# RSL15 register map
Vendor: ONSemiconductor; Series: RSL15 Series; File version: 1.0
CPU: CM33 r0p4, little endian, MPU, FPU, 3 interrupt priority bits
Registers are 32-bit, read-write, reset 0x0 unless marked. A register's access mark holds for its fields unless they carry their own. Offsets are from the block's base; [hi:lo] are bit positions.

## SPI0 — SPI Interface
Base 0x40000B00
Same registers: SPI1 0x40000C00
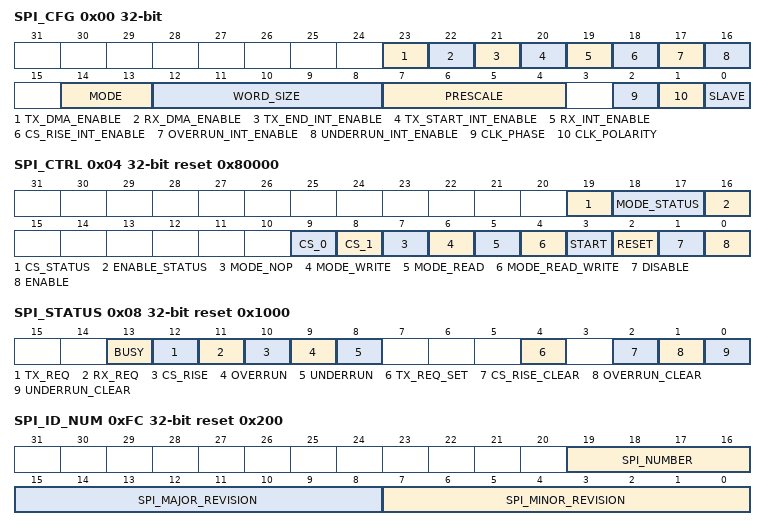
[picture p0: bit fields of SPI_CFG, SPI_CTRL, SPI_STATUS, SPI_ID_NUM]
0x00 SPI_CFG — SPI Configuration Register
  [23] TX_DMA_ENABLE — Enable/disable the TX DMA request
    0=SPI_TX_DMA_DISABLE (No TX DMA request is generated); 1=SPI_TX_DMA_ENABLE (A TX DMA request is generated when TX buffer is empty)
  [22] RX_DMA_ENABLE — Enable/disable the RX DMA request
    0=SPI_RX_DMA_DISABLE (No RX DMA request is generated); 1=SPI_RX_DMA_ENABLE (An RX DMA request is generated when RX buffer is full)
  [21] TX_END_INT_ENABLE — Enable/disable the TX interrupt
    0=SPI_TX_END_INT_DISABLE (No TX interrupt is raised); 1=SPI_TX_END_INT_ENABLE (A TX interrupt is raised when a TX data transmission is finished)
  [20] TX_START_INT_ENABLE — Enable/disable the TX interrupt
    0=SPI_TX_START_INT_DISABLE (No TX interrupt is raised); 1=SPI_TX_START_INT_ENABLE (A TX interrupt is raised when a new TX data send by the SPI interface is started)
  [19] RX_INT_ENABLE — Enable/disable the RX interrupt
    0=SPI_RX_INT_DISABLE (No RX interrupt is raised); 1=SPI_RX_INT_ENABLE (An RX interrupt is raised when new data is received by the SPI interface)
  [18] CS_RISE_INT_ENABLE — Enable/disable the CS rise interrupt (slave mode only)
    0=SPI_CS_RISE_INT_DISABLE (No interrupt is raised when the CS rises in slave mode); 1=SPI_CS_RISE_INT_ENABLE (A common interrupt is raised when the CS rises in slave mode)
  [17] OVERRUN_INT_ENABLE — Enable/disable the overrun interrupt
    0=SPI_OVERRUN_INT_DISABLE (No interrupt is raised when an overrun is detected); 1=SPI_OVERRUN_INT_ENABLE (A common interrupt is raised when an overrun occurs on the SPI interface)
  [16] UNDERRUN_INT_ENABLE — Enable/disable the underrun interrupt
    0=SPI_UNDERRUN_INT_DISABLE (No interrupt is raised when an underrun is detected); 1=SPI_UNDERRUN_INT_ENABLE (A common interrupt is raised when an underrun occurs on the SPI interface)
  [14:13] MODE — Select the SPI master mode (ignored in slave mode)
    0=SPI_MODE_SPI (SPI normal mode (separate RX and TX data)); 1=SPI_MODE_DSPI (SPI dual mode (two bideractional data pins)); 2=SPI_MODE_QSPI (SPI quad mode (four bidirectional data pins))
  [12:8] WORD_SIZE — Select the SPI word size (word size = SPI_WORD_SIZE + 1)
    0=SPI_WORD_SIZE_1 (SPI transfers use 1-bit words); 3=SPI_WORD_SIZE_4 (SPI transfers use 4-bit words); 7=SPI_WORD_SIZE_8 (SPI transfers use 8-bit words); 15=SPI_WORD_SIZE_16 (SPI transfers use 16-bit words); 23=SPI_WORD_SIZE_24 (SPI transfers use 24-bit words); 31=SPI_WORD_SIZE_32 (SPI transfers use 32-bit words)
  [7:4] PRESCALE — Prescale the SPI clock for master mode
    0=SPI_PRESCALE_2 (Prescale the SPI interface clock by 2); 1=SPI_PRESCALE_4 (Prescale the SPI interface clock by 4); 2=SPI_PRESCALE_8 (Prescale the SPI interface clock by 8); 3=SPI_PRESCALE_16 (Prescale the SPI interface clock by 16); 4=SPI_PRESCALE_32 (Prescale the SPI interface clock by 32); 5=SPI_PRESCALE_64 (Prescale the SPI interface clock by 64); 6=SPI_PRESCALE_128 (Prescale the SPI interface clock by 128); 7=SPI_PRESCALE_256 (Prescale the SPI interface clock by 256); 8=SPI_PRESCALE_512 (Prescale the SPI interface clock by 512); 9=SPI_PRESCALE_1024 (Prescale the SPI interface clock by 1024)
  [2] CLK_PHASE — Select the SPI clock phase
    0=SPI_CLK_PHASE_RISING (In both master and slave modes SERO changes on the falling edge of the SPI clock. The SERI is sampled at the rising edge of the SPI clock); 1=SPI_CLK_PHASE_FALLING (In both master and slave modes SERO changes on the rising edge of the SPI clock. The SERI is sampled at the falling edge of the SPI clock)
  [1] CLK_POLARITY — Select the SPI clock polarity
    0=SPI_CLK_POLARITY_NORMAL (In Master mode in idle state the spi clock polarity is low); 1=SPI_CLK_POLARITY_INVERSE (In Master mode in idle state the spi clock polarity is high)
  [0] SLAVE — Use the SPI interface as master or slave
    0=SPI_SELECT_MASTER (Use the SPI interface in master mode); 1=SPI_SELECT_SLAVE (Use the SPI interface in slave mode)
0x04 SPI_CTRL reset 0x80000 (reset mask 0xF0000) — SPI Control Register
  [19] CS_STATUS ro — SPI CS status
    0=SPI_STATUS_CS_0 (SPI CS is low); 1=SPI_STATUS_CS_1 (SPI CS is high)
  [18:17] MODE_STATUS ro — SPI mode status
    0=SPI_STATUS_MODE_NOP (Mode is no operation (not allowed in DSPI and QSPI modes)); 1=SPI_STATUS_MODE_WRITE (Mode is write data); 2=SPI_STATUS_MODE_READ (Mode is read data); 3=SPI_STATUS_MODE_READ_WRITE (Mode is read and write data (not allowed in DSPI and QSPI modes))
  [16] ENABLE_STATUS ro — SPI enable status
    0=SPI_STATUS_DISABLED (SPI interface is disabled); 1=SPI_STATUS_ENABLED (SPI interface is enabled)
  [9] CS_0 wo — Lower the SPI chip-select line (master mode)
    1=SPI_CS_0 (Set the SPI CS signal low)
  [8] CS_1 wo — Raise the SPI chip-select line (master mode)
    1=SPI_CS_1 (Set the SPI CS signal high)
  [7] MODE_NOP wo — Set mode to no operation
    1=SPI_MODE_NOP (Set the mode to no operation)
  [6] MODE_WRITE wo — Set mode to read operation
    1=SPI_MODE_WRITE (Set the mode to write operation)
  [5] MODE_READ wo — Set mode to write operation
    1=SPI_MODE_READ (Set the mode to read operation)
  [4] MODE_READ_WRITE wo — Set mode to read and write operation
    1=SPI_MODE_READ_WRITE (Set the mode to read and write operation (not allowed in DSPI and QSPI modes))
  [3] START wo — Start a data transfer in master read mode
    1=SPI_START_READ (Start a transfer on the SPI interface (master read mode only))
  [2] RESET wo — Reset the SPI interface
    1=SPI_RESET (Reset the SPI interface)
  [1] DISABLE wo — Disable the SPI interface
    1=SPI_DISABLE (Disable the SPI interface)
  [0] ENABLE wo — Enable the SPI interface
    1=SPI_ENABLE (Enable the SPI interface)
0x08 SPI_STATUS reset 0x1000 (reset mask 0x3F00)
  [13] BUSY ro — Indicate that the reception or transmission of the data is ongoing
    0=SPI_IDLE; 1=SPI_BUSY
  [12] TX_REQ ro — Indicate that TX data can be written
    0=SPI_TX_NO_REQ (SPI TX data has already been written); 1=SPI_TX_REQ (SPI TX data can be written)
  [11] RX_REQ ro — Indicate that RX data can be read
    0=SPI_RX_NO_REQ (No new SPI RX data available); 1=SPI_RX_REQ (New SPI RX data available)
  [10] CS_RISE ro — Indicate that CS has risen in slave mode
    0=SPI_CS_RISE_FALSE (CS did not rise in slave mode); 1=SPI_CS_RISE_TRUE (CS has risen in slave mode)
  [9] OVERRUN ro — Indicate that an overrun has occurred when receiving data on the SPI interface
    0=SPI_OVERRUN_FALSE (No SPI input overrun detected); 1=SPI_OVERRUN_TRUE (SPI input overrun detected)
  [8] UNDERRUN ro — Indicate that an underrun has occurred when transmitting data on the SPI interface
    0=SPI_UNDERRUN_FALSE (No SPI input underrun detected); 1=SPI_UNDERRUN_TRUE (SPI input underrun detected)
  [4] TX_REQ_SET wo — Set TX_REQ status flag and clear internal TX buffer status
    1=SPI_TX_REQ_SET (Set the TX_REQ status flag and clear internal TX buffer status)
  [2] CS_RISE_CLEAR wo — Clear the CS rise status flag
    1=SPI_CS_RISE_CLEAR (Clear the SPI CS rise status bit)
  [1] OVERRUN_CLEAR wo — Clear the overrun status flag
    1=SPI_OVERRUN_CLEAR (Clear the SPI overrun status bit)
  [0] UNDERRUN_CLEAR wo — Clear the underrun status flag
    1=SPI_UNDERRUN_CLEAR (Clear the SPI underrun status bit)
0x0C SPI_TX_DATA — SPI Transmit Data Register
  [31:0] TX_DATA — Single word buffer for data to be transmitted. When in master write or read_write mode, the transaction is started automatically
0x10 SPI_RX_DATA ro — SPI Received Data Register
  [31:0] RX_DATA — Single word buffer for received data. When in master read mode, a new transaction is started automatically
0x14 SPI_RX_DATA_NO_START ro — SPI Received Data No Start Register
  [31:0] RX_DATA — Single word buffer for received data. Does not start a new transaction in master read mode, but does clear the RX_REQ flag
0x18 SPI_RX_DATA_MIRROR ro — SPI Received Data Mirror Register
  [31:0] RX_DATA — Single word buffer for received data. Does not start a new transaction and does clear the RX_REQ flag
0xFC SPI_ID_NUM ro reset 0x200 — SPI ID number
  [19:16] SPI_NUMBER — SPI Instance number
  [15:8] SPI_MAJOR_REVISION — SPI Major Revision number
    2=SPI_MAJOR_REVISION (SPI revision 2.0)
  [7:0] SPI_MINOR_REVISION — SPI Minor Revision number
    0=SPI_MINOR_REVISION (SPI revision 2.0)
